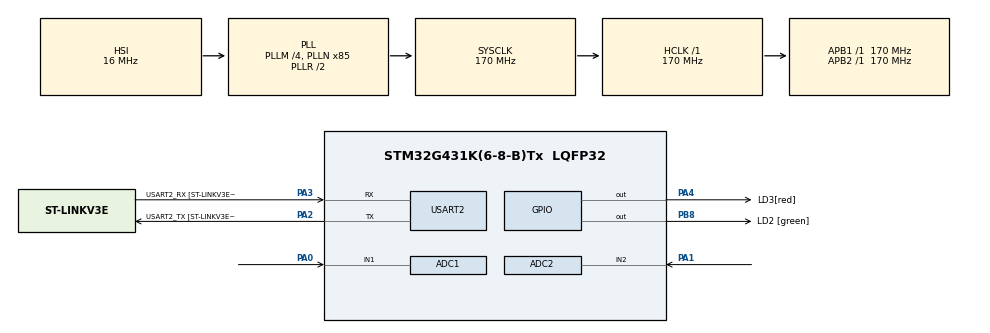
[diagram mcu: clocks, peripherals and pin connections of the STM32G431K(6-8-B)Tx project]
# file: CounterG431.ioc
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ADC1.Channel-0\#ChannelRegularConversion=ADC_CHANNEL_1
ADC1.ContinuousConvMode=ENABLE
ADC1.LowPowerAutoWait=ENABLE
ADC1.NbrOfConversionFlag=1
ADC1.OffsetNumber-0\#ChannelRegularConversion=ADC_OFFSET_NONE
ADC1.Rank-0\#ChannelRegularConversion=1
ADC1.Resolution=ADC_RESOLUTION_6B
ADC1.SamplingTime-0\#ChannelRegularConversion=ADC_SAMPLETIME_2CYCLES_5
ADC1.master=1
ADC2.Channel-0\#ChannelRegularConversion=ADC_CHANNEL_2
ADC2.ContinuousConvMode=ENABLE
ADC2.LowPowerAutoWait=ENABLE
ADC2.NbrOfConversionFlag=1
ADC2.OffsetNumber-0\#ChannelRegularConversion=ADC_OFFSET_NONE
ADC2.Rank-0\#ChannelRegularConversion=1
ADC2.Resolution=ADC_RESOLUTION_6B
ADC2.SamplingTime-0\#ChannelRegularConversion=ADC_SAMPLETIME_2CYCLES_5
Mcu.Family=STM32G4
Mcu.Name=STM32G431K(6-8-B)Tx
Mcu.Package=LQFP32
NVIC.PriorityGroup=NVIC_PRIORITYGROUP_4
NVIC.TIM6_DAC_IRQn=true\:0\:0\:false\:false\:true\:true\:true\:true
NVIC.USART2_IRQn=true\:0\:0\:false\:false\:true\:true\:true\:true
PA0.Mode=IN1-Single-Ended
PA0.Signal=ADC1_IN1
PA1.Mode=IN2-Single-Ended
PA1.Signal=ADC2_IN2
PA13.GPIO_Label=T_SWDIO
PA13.Mode=Serial_Wire
PA13.Signal=SYS_JTMS-SWDIO
PA14.GPIO_Label=T_SWCLK
PA14.Mode=Serial_Wire
PA14.Signal=SYS_JTCK-SWCLK
PA2.GPIO_Label=USART2_TX [ST-LINKV3E_VCP_RX]
PA2.Mode=Asynchronous
PA2.Signal=USART2_TX
PA3.GPIO_Label=USART2_RX [ST-LINKV3E_VCP_TX]
PA3.Mode=Asynchronous
PA3.Signal=USART2_RX
PA4.GPIO_Label=LD3[red]
PA4.Signal=GPIO_Output
PB3.GPIO_Label=T_SWO
PB3.Signal=SYS_JTDO-SWO
PB8-BOOT0.GPIO_Label=LD2 [green]
PB8-BOOT0.Signal=GPIO_Output
ProjectManager.HeapSize=0x200
ProjectManager.StackSize=0x400
ProjectManager.TargetToolchain=Makefile
RCC.ADC12Freq_Value=170000000
RCC.AHBFreq_Value=170000000
RCC.APB1Freq_Value=170000000
RCC.APB1TimFreq_Value=170000000
RCC.APB2Freq_Value=170000000
RCC.APB2TimFreq_Value=170000000
RCC.CortexFreq_Value=170000000
RCC.EXTERNAL_CLOCK_VALUE=12288000
RCC.HCLKFreq_Value=170000000
RCC.HSE_VALUE=8000000
RCC.HSI48_VALUE=48000000
RCC.HSI_VALUE=16000000
RCC.LSE_VALUE=32768
RCC.PLLM=RCC_PLLM_DIV4
RCC.PLLN=85
RCC.SYSCLKFreq_VALUE=170000000
RCC.SYSCLKSource=RCC_SYSCLKSOURCE_PLLCLK
RCC.USBFreq_Value=170000000
RCC.VCOOutputFreq_Value=340000000
TIM6.PeriodNoDither=1000-1
TIM6.Prescaler=170-1
USART2.VirtualMode-Asynchronous=VM_ASYNC
USART2.WordLength=WORDLENGTH_8B
VP_TIM6_VS_ClockSourceINT.Mode=Enable_Timer
board=NUCLEO-G431KB

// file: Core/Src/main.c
/* USER CODE BEGIN Header */
/**
  ******************************************************************************
  * @file           : main.c
  * @brief          : Main program body
  ******************************************************************************
  * @attention
  *
  * Copyright (c) 2022 STMicroelectronics.
  * All rights reserved.
  *
  * This software is licensed under terms that can be found in the LICENSE file
  * in the root directory of this software component.
  * If no LICENSE file comes with this software, it is provided AS-IS.
  *
  ******************************************************************************
  */
/* USER CODE END Header */
#include "main.h"
#include "adc.h"
#include "tim.h"
#include "usart.h"
#include "gpio.h"

/* USER CODE BEGIN Includes */
#include "variable.h"
#include "algo.h"

/* USER CODE END Includes */

void SystemClock_Config(void);

int main(void)
{

  /* MCU Configuration--------------------------------------------------------*/

  /* Reset of all peripherals, Initializes the Flash interface and the Systick. */
  HAL_Init();

  /* Configure the system clock */
  SystemClock_Config();

  /* Initialize all configured peripherals */
  MX_GPIO_Init();
  MX_USART2_UART_Init();
  MX_ADC1_Init();
  MX_TIM6_Init();
  MX_ADC2_Init();
  /* USER CODE BEGIN 2 */
  HAL_ADC_Start(&hadc1);
  HAL_ADC_Start(&hadc2);
  HAL_TIM_Base_Start_IT(&htim6);
  HAL_UART_Receive_IT(&huart2, &gh_rx_data, 1);
  init(); //초기화 Algo.c
  /* USER CODE END 2 */

  /* Infinite loop */
  /* USER CODE BEGIN WHILE */
  while (1)
  {
    loop(); //루프문 Algo.c
    /* USER CODE END WHILE */

  }
}

void SystemClock_Config(void)
{
  RCC_OscInitTypeDef RCC_OscInitStruct = {0};
  RCC_ClkInitTypeDef RCC_ClkInitStruct = {0};

  /** Configure the main internal regulator output voltage
  */
  HAL_PWREx_ControlVoltageScaling(PWR_REGULATOR_VOLTAGE_SCALE1_BOOST);

  /** Initializes the RCC Oscillators according to the specified parameters
  * in the RCC_OscInitTypeDef structure.
  */
  RCC_OscInitStruct.OscillatorType = RCC_OSCILLATORTYPE_HSI;
  RCC_OscInitStruct.HSIState = RCC_HSI_ON;
  RCC_OscInitStruct.HSICalibrationValue = RCC_HSICALIBRATION_DEFAULT;
  RCC_OscInitStruct.PLL.PLLState = RCC_PLL_ON;
  RCC_OscInitStruct.PLL.PLLSource = RCC_PLLSOURCE_HSI;
  RCC_OscInitStruct.PLL.PLLM = RCC_PLLM_DIV4;
  RCC_OscInitStruct.PLL.PLLN = 85;
  RCC_OscInitStruct.PLL.PLLP = RCC_PLLP_DIV2;
  RCC_OscInitStruct.PLL.PLLQ = RCC_PLLQ_DIV2;
  RCC_OscInitStruct.PLL.PLLR = RCC_PLLR_DIV2;
  if (HAL_RCC_OscConfig(&RCC_OscInitStruct) != HAL_OK)
  {
    Error_Handler();
  }

  /** Initializes the CPU, AHB and APB buses clocks
  */
  RCC_ClkInitStruct.ClockType = RCC_CLOCKTYPE_HCLK|RCC_CLOCKTYPE_SYSCLK
                              |RCC_CLOCKTYPE_PCLK1|RCC_CLOCKTYPE_PCLK2;
  RCC_ClkInitStruct.SYSCLKSource = RCC_SYSCLKSOURCE_PLLCLK;
  RCC_ClkInitStruct.AHBCLKDivider = RCC_SYSCLK_DIV1;
  RCC_ClkInitStruct.APB1CLKDivider = RCC_HCLK_DIV1;
  RCC_ClkInitStruct.APB2CLKDivider = RCC_HCLK_DIV1;

  if (HAL_RCC_ClockConfig(&RCC_ClkInitStruct, FLASH_LATENCY_4) != HAL_OK)
  {
    Error_Handler();
  }
}

void Error_Handler(void)
{
  __disable_irq();
  while (1)
  {
  }
}
